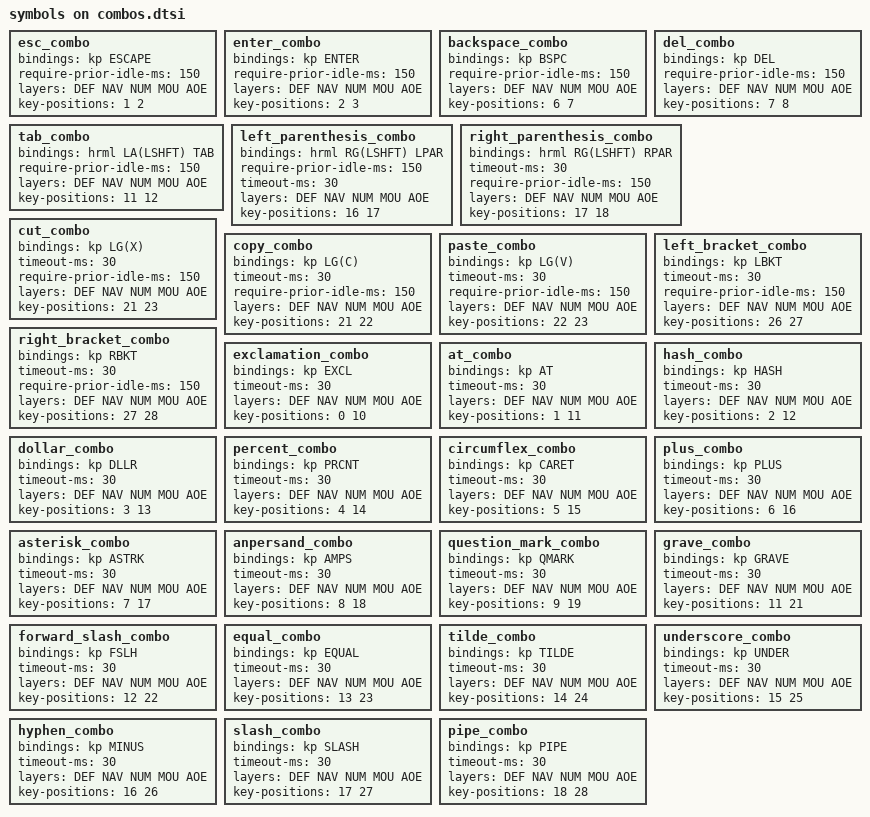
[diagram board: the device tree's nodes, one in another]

        // Horizontal combos

        esc_combo {
            bindings = <&kp ESCAPE>;
            require-prior-idle-ms = <150>;
            layers = <DEF NAV NUM MOU AOE>;
            key-positions = <1 2>;
        };

        enter_combo {
            bindings = <&kp ENTER>;
            require-prior-idle-ms = <150>;
            layers = <DEF NAV NUM MOU AOE>;
            key-positions = <2 3>;
        };

        backspace_combo {
            bindings = <&kp BSPC>;
            require-prior-idle-ms = <150>;
            layers = <DEF NAV NUM MOU AOE>;
            key-positions = <6 7>;
        };

        del_combo {
            bindings = <&kp DEL>;
            require-prior-idle-ms = <150>;
            layers = <DEF NAV NUM MOU AOE>;
            key-positions = <7 8>;
        };

        tab_combo {
            bindings = <&hrml LA(LSHFT) TAB>;
            require-prior-idle-ms = <150>;
            layers = <DEF NAV NUM MOU AOE>;
            key-positions = <11 12>;
        };
        
        left_parenthesis_combo {
            bindings = <&hrml RG(LSHFT) LPAR>;
            require-prior-idle-ms = <150>;
            timeout-ms = <30>;
            layers = <DEF NAV NUM MOU AOE>;
            key-positions = <16 17>;
        };
        
        right_parenthesis_combo {
            bindings = <&hrml RG(LSHFT) RPAR>;
            timeout-ms = <30>;
            require-prior-idle-ms = <150>;
            layers = <DEF NAV NUM MOU AOE>;
            key-positions = <17 18>;
        };

        cut_combo {
            bindings = <&kp LG(X)>;
            timeout-ms = <30>;
            require-prior-idle-ms = <150>;
            layers = <DEF NAV NUM MOU AOE>;
            key-positions = <21 23>;
        };

        copy_combo {
            bindings = <&kp LG(C)>;
            timeout-ms = <30>;
            require-prior-idle-ms = <150>;
            layers = <DEF NAV NUM MOU AOE>;
            key-positions = <21 22>;
        };

        paste_combo {
            bindings = <&kp LG(V)>;
            timeout-ms = <30>;
            require-prior-idle-ms = <150>;
            layers = <DEF NAV NUM MOU AOE>;
            key-positions = <22 23>;
        };

        left_bracket_combo {
            bindings = <&kp LBKT>;
            timeout-ms = <30>;
            require-prior-idle-ms = <150>;
            layers = <DEF NAV NUM MOU AOE>;
            key-positions = <26 27>;
        };

        right_bracket_combo {
            bindings = <&kp RBKT>;
            timeout-ms = <30>;
            require-prior-idle-ms = <150>;
            layers = <DEF NAV NUM MOU AOE>;
            key-positions = <27 28>;
        };

        // Vertical symbols combo

        exclamation_combo {
            bindings = <&kp EXCL>;
            timeout-ms = <30>;
            layers = <DEF NAV NUM MOU AOE>;
            key-positions = <0 10>;
        };

        at_combo {
            bindings = <&kp AT>;
            timeout-ms = <30>;
            layers = <DEF NAV NUM MOU AOE>;
            key-positions = <1 11>;
        };

        hash_combo {
            bindings = <&kp HASH>;
            timeout-ms = <30>;
            layers = <DEF NAV NUM MOU AOE>;
            key-positions = <2 12>;
        };

        dollar_combo {
            bindings = <&kp DLLR>;
            timeout-ms = <30>;
            layers = <DEF NAV NUM MOU AOE>;
            key-positions = <3 13>;
        };

        percent_combo {
            bindings = <&kp PRCNT>;
            timeout-ms = <30>;
            layers = <DEF NAV NUM MOU AOE>;
            key-positions = <4 14>;
        };

        circumflex_combo {
            bindings = <&kp CARET>;
            timeout-ms = <30>;
            layers = <DEF NAV NUM MOU AOE>;
            key-positions = <5 15>;
        };

        plus_combo {
            bindings = <&kp PLUS>;
            timeout-ms = <30>;
            layers = <DEF NAV NUM MOU AOE>;
            key-positions = <6 16>;
        };

        asterisk_combo {
            bindings = <&kp ASTRK>;
            timeout-ms = <30>;
            layers = <DEF NAV NUM MOU AOE>;
            key-positions = <7 17>;
        };

        anpersand_combo {
            bindings = <&kp AMPS>;
            timeout-ms = <30>;
            layers = <DEF NAV NUM MOU AOE>;
            key-positions = <8 18>;
        };

        question_mark_combo {
            bindings = <&kp QMARK>;
            timeout-ms = <30>;
            layers = <DEF NAV NUM MOU AOE>;
            key-positions = <9 19>;
        };

        grave_combo {
            bindings = <&kp GRAVE>;
            timeout-ms = <30>;
            layers = <DEF NAV NUM MOU AOE>;
            key-positions = <11 21>;
        };

        forward_slash_combo {
            bindings = <&kp FSLH>;
            timeout-ms = <30>;
            layers = <DEF NAV NUM MOU AOE>;
            key-positions = <12 22>;
        };

        equal_combo {
            bindings = <&kp EQUAL>;
            timeout-ms = <30>;
            layers = <DEF NAV NUM MOU AOE>;
            key-positions = <13 23>;
        };

        tilde_combo {
            bindings = <&kp TILDE>;
            timeout-ms = <30>;
            layers = <DEF NAV NUM MOU AOE>;
            key-positions = <14 24>;
        };

        underscore_combo {
            bindings = <&kp UNDER>;
            timeout-ms = <30>;
            layers = <DEF NAV NUM MOU AOE>;
            key-positions = <15 25>;
        };

        hyphen_combo {
            bindings = <&kp MINUS>;
            timeout-ms = <30>;
            layers = <DEF NAV NUM MOU AOE>;
            key-positions = <16 26>;
        };

        slash_combo {
            bindings = <&kp SLASH>;
            timeout-ms = <30>;
            layers = <DEF NAV NUM MOU AOE>;
            key-positions = <17 27>;
        };

        pipe_combo {
            bindings = <&kp PIPE>;
            timeout-ms = <30>;
            layers = <DEF NAV NUM MOU AOE>;
            key-positions = <18 28>;
        };
        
